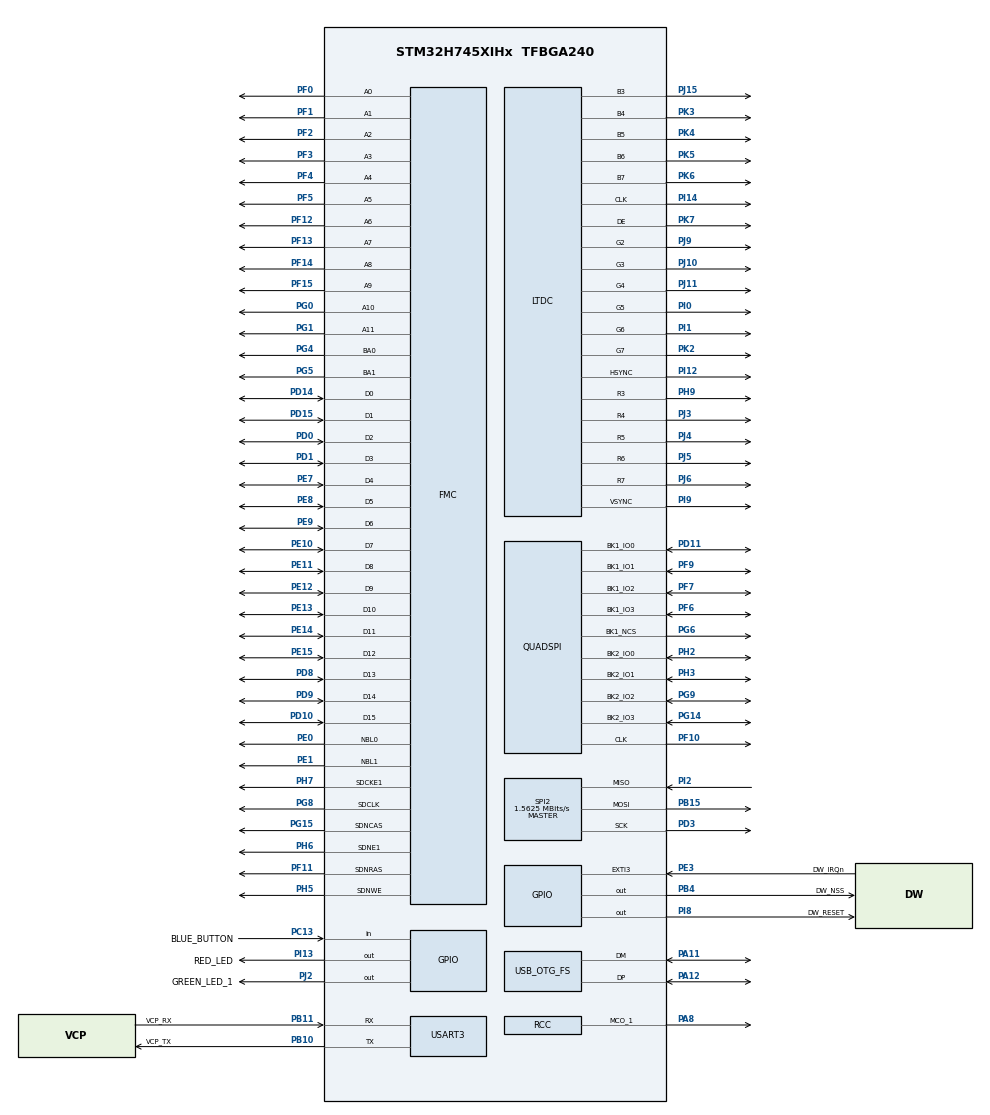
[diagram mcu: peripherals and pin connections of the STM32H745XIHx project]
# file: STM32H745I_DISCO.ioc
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CORTEX_M7.AccessPermission-Cortex_Memory_Protection_Unit_Region0_Settings=MPU_REGION_FULL_ACCESS
CORTEX_M7.AccessPermission-Cortex_Memory_Protection_Unit_Region1_Settings=MPU_REGION_FULL_ACCESS
CORTEX_M7.BaseAddress-Cortex_Memory_Protection_Unit_Region0_Settings=0xD0000000
CORTEX_M7.BaseAddress-Cortex_Memory_Protection_Unit_Region1_Settings=0x90000000
CORTEX_M7.CPU_DCache=Enabled
CORTEX_M7.CPU_ICache=Enabled
CORTEX_M7.DisableExec-Cortex_Memory_Protection_Unit_Region0_Settings=MPU_INSTRUCTION_ACCESS_DISABLE
CORTEX_M7.DisableExec-Cortex_Memory_Protection_Unit_Region1_Settings=MPU_INSTRUCTION_ACCESS_DISABLE
CORTEX_M7.Enable-Cortex_Memory_Protection_Unit_Region0_Settings=MPU_REGION_ENABLE
CORTEX_M7.Enable-Cortex_Memory_Protection_Unit_Region1_Settings=MPU_REGION_ENABLE
CORTEX_M7.Enable-Cortex_Memory_Protection_Unit_Region2_Settings=__NULL
CORTEX_M7.Enable-Cortex_Memory_Protection_Unit_Region3_Settings=__NULL
CORTEX_M7.Enable-Cortex_Memory_Protection_Unit_Region4_Settings=__NULL
CORTEX_M7.IsBufferable-Cortex_Memory_Protection_Unit_Region0_Settings=MPU_ACCESS_BUFFERABLE
CORTEX_M7.IsBufferable-Cortex_Memory_Protection_Unit_Region1_Settings=MPU_ACCESS_BUFFERABLE
CORTEX_M7.IsCacheable-Cortex_Memory_Protection_Unit_Region0_Settings=MPU_ACCESS_CACHEABLE
CORTEX_M7.IsCacheable-Cortex_Memory_Protection_Unit_Region1_Settings=MPU_ACCESS_CACHEABLE
CORTEX_M7.IsShareable-Cortex_Memory_Protection_Unit_Region1_Settings=MPU_ACCESS_NOT_SHAREABLE
CORTEX_M7.MPU_Control=MPU_PRIVILEGED_DEFAULT
CORTEX_M7.Size-Cortex_Memory_Protection_Unit_Region0_Settings=MPU_REGION_SIZE_1MB
CORTEX_M7.Size-Cortex_Memory_Protection_Unit_Region1_Settings=MPU_REGION_SIZE_128MB
CortexM4.IPs=CORTEX_M4\:I,DEBUG,FATFS_M4\:I,FREERTOS_M4\:I,IWDG2\:I,OPENAMP_M4\:I,PDM2PCM_M4\:I,PWR,RCC,RESMGR_UTILITY,SYS_M4\:I,USB_DEVICE_M4\:I,USB_HOST_M4\:I,VREFBUF,WWDG2\:I,DMA,BDMA,MDMA,NVIC2\:I
CortexM7.IPs=CORTEX_M7\:I,DEBUG\:I,FATFS_M7\:I,FREERTOS_M7\:I,IWDG1\:I,OPENAMP_M7\:I,PDM2PCM_M7\:I,PWR\:I,RCC\:I,RESMGR_UTILITY\:I,SYS\:I,USB_DEVICE_M7\:I,USB_HOST_M7\:I,VREFBUF\:I,WWDG1\:I,DMA\:I,BDMA\:I,MDMA\:I,NVIC1\:I,TIM6\:I,CRC\:I,LTDC\:I,DMA2D\:I,FMC\:I,QUADSPI\:I,STMicroelectronics.X-CUBE-TOUCHGFX.4.18.1_M7\:I,USART3\:I,SPI2\:I,USB_OTG_FS\:I
CortexM7.Pins=PB4 (NJTRST),PE3,PC13,PI8,PI13,PJ2
DMA2D.ColorMode=DMA2D_OUTPUT_RGB565
DMA2D.Mode=DMA2D_R2M
FMC.CASLatency2=FMC_SDRAM_CAS_LATENCY_2
FMC.ExitSelfRefreshDelay2=6
FMC.LoadToActiveDelay2=2
FMC.RCDDelay2=2
FMC.RPDelay1=2
FMC.RPDelay2=2
FMC.ReadBurst2=FMC_SDRAM_RBURST_ENABLE
FMC.RowCycleDelay1=6
FMC.RowCycleDelay2=6
FMC.SDClockPeriod2=FMC_SDRAM_CLOCK_PERIOD_2
FMC.SelfRefreshTime2=4
FMC.WriteRecoveryTime2=2
FREERTOS_M7.Tasks01=defaultTask,8,128,StartDefaultTask,Default,NULL,Dynamic,NULL,NULL;TouchGFXTask,24,3048,TouchGFX_Task,As weak,NULL,Dynamic,NULL,NULL
FREERTOS_M7.configTOTAL_HEAP_SIZE=32768
FREERTOS_M7.configUSE_NEWLIB_REENTRANT=0
LTDC.ActiveH=272
LTDC.ActiveW=480
LTDC.Alpha0_L0=0
LTDC.Alpha_L0=255
LTDC.BlendingFactor1_L0=LTDC_BLENDING_FACTOR1_CA
LTDC.BlendingFactor2_L0=LTDC_BLENDING_FACTOR2_CA
LTDC.FBStartAdress_L0=0xD0000000
LTDC.HBP=13
LTDC.HFP=32
LTDC.HSync=41
LTDC.ImageHeight_L0=272
LTDC.ImageWidth_L0=480
LTDC.Layers=0
LTDC.PixelFormat_L0=LTDC_PIXEL_FORMAT_RGB565
LTDC.VBP=2
LTDC.VSync=10
LTDC.WindowX1_L0=480
LTDC.WindowY1_L0=272
Mcu.Family=STM32H7
Mcu.Name=STM32H745XIHx
Mcu.Package=TFBGA240
NVIC1.DMA2D_IRQn=true\:5\:0\:false\:false\:true\:true\:true\:true
NVIC1.LTDC_IRQn=true\:5\:0\:false\:false\:true\:true\:true\:true
NVIC1.OTG_FS_IRQn=true\:5\:0\:false\:false\:true\:true\:false\:true
NVIC1.PriorityGroup=NVIC_PRIORITYGROUP_4
NVIC1.QUADSPI_IRQn=true\:5\:0\:false\:false\:true\:true\:true\:true
NVIC1.TIM6_DAC_IRQn=true\:15\:0\:false\:false\:true\:false\:false\:true
NVIC1.TimeBase=TIM6_DAC_IRQn
NVIC1.TimeBaseIP=TIM6
NVIC2.PriorityGroup=NVIC_PRIORITYGROUP_4
PA11.Mode=Device_Only
PA11.PinAttribute=CortexM7
PA11.Signal=USB_OTG_FS_DM
PA12.Mode=Device_Only
PA12.PinAttribute=CortexM7
PA12.Signal=USB_OTG_FS_DP
PA8.Mode=Clock-out-1
PA8.PinAttribute=CortexM7
PA8.Signal=RCC_MCO_1
PB10.GPIO_Label=VCP_TX
PB10.GPIO_Speed=GPIO_SPEED_FREQ_VERY_HIGH
PB10.Mode=Asynchronous
PB10.PinAttribute=CortexM7
PB10.Signal=USART3_TX
PB11.GPIO_Label=VCP_RX
PB11.GPIO_Speed=GPIO_SPEED_FREQ_VERY_HIGH
PB11.Mode=Asynchronous
PB11.PinAttribute=CortexM7
PB11.Signal=USART3_RX
PB15.GPIO_Speed=GPIO_SPEED_FREQ_VERY_HIGH
PB15.Mode=Full_Duplex_Master
PB15.PinAttribute=CortexM7
PB15.Signal=SPI2_MOSI
PB4\ (NJTRST).GPIO_Label=DW_NSS
PB4\ (NJTRST).GPIO_Speed=GPIO_SPEED_FREQ_VERY_HIGH
PB4\ (NJTRST).PinAttribute=CortexM7
PB4\ (NJTRST).PinState=GPIO_PIN_SET
PB4\ (NJTRST).Signal=GPIO_Output
PC13.GPIO_Label=BLUE_BUTTON
PC13.GPIO_PuPd=GPIO_PULLDOWN
PC13.PinAttribute=CortexM7
PC13.Signal=GPIO_Input
PD0.PinAttribute=CortexM7
PD0.Signal=FMC_D2_DA2
PD1.PinAttribute=CortexM7
PD1.Signal=FMC_D3_DA3
PD10.PinAttribute=CortexM7
PD10.Signal=FMC_D15_DA15
PD11.GPIO_Speed=GPIO_SPEED_FREQ_VERY_HIGH
PD11.Mode=Dual_Bank
PD11.PinAttribute=CortexM7
PD11.Signal=QUADSPI_BK1_IO0
PD14.PinAttribute=CortexM7
PD14.Signal=FMC_D0_DA0
PD15.PinAttribute=CortexM7
PD15.Signal=FMC_D1_DA1
PD3.GPIO_Speed=GPIO_SPEED_FREQ_VERY_HIGH
PD3.Mode=Full_Duplex_Master
PD3.PinAttribute=CortexM7
PD3.Signal=SPI2_SCK
PD8.PinAttribute=CortexM7
PD8.Signal=FMC_D13_DA13
PD9.PinAttribute=CortexM7
PD9.Signal=FMC_D14_DA14
PE0.PinAttribute=CortexM7
PE0.Signal=FMC_NBL0
PE1.PinAttribute=CortexM7
PE1.Signal=FMC_NBL1
PE10.PinAttribute=CortexM7
PE10.Signal=FMC_D7_DA7
PE11.PinAttribute=CortexM7
PE11.Signal=FMC_D8_DA8
PE12.PinAttribute=CortexM7
PE12.Signal=FMC_D9_DA9
PE13.PinAttribute=CortexM7
PE13.Signal=FMC_D10_DA10
PE14.PinAttribute=CortexM7
PE14.Signal=FMC_D11_DA11
PE15.PinAttribute=CortexM7
PE15.Signal=FMC_D12_DA12
PE3.GPIO_Label=DW_IRQn
PE3.GPIO_PuPd=GPIO_PULLDOWN
PE3.PinAttribute=CortexM7
PE3.Signal=GPXTI3
PE7.PinAttribute=CortexM7
PE7.Signal=FMC_D4_DA4
PE8.PinAttribute=CortexM7
PE8.Signal=FMC_D5_DA5
PE9.PinAttribute=CortexM7
PE9.Signal=FMC_D6_DA6
PF0.PinAttribute=CortexM7
PF0.Signal=FMC_A0
PF1.PinAttribute=CortexM7
PF1.Signal=FMC_A1
PF10.GPIO_Speed=GPIO_SPEED_FREQ_VERY_HIGH
PF10.Mode=Dual_Bank
PF10.PinAttribute=CortexM7
PF10.Signal=QUADSPI_CLK
PF11.PinAttribute=CortexM7
PF11.Signal=FMC_SDNRAS
PF12.PinAttribute=CortexM7
PF12.Signal=FMC_A6
PF13.PinAttribute=CortexM7
PF13.Signal=FMC_A7
PF14.PinAttribute=CortexM7
PF14.Signal=FMC_A8
PF15.PinAttribute=CortexM7
PF15.Signal=FMC_A9
PF2.PinAttribute=CortexM7
PF2.Signal=FMC_A2
PF3.PinAttribute=CortexM7
PF3.Signal=FMC_A3
PF4.PinAttribute=CortexM7
PF4.Signal=FMC_A4
PF5.PinAttribute=CortexM7
PF5.Signal=FMC_A5
PF6.GPIO_Speed=GPIO_SPEED_FREQ_VERY_HIGH
PF6.Mode=Dual_Bank
PF6.PinAttribute=CortexM7
PF6.Signal=QUADSPI_BK1_IO3
PF7.GPIO_Speed=GPIO_SPEED_FREQ_VERY_HIGH
PF7.Mode=Dual_Bank
PF7.PinAttribute=CortexM7
PF7.Signal=QUADSPI_BK1_IO2
PF9.GPIO_Speed=GPIO_SPEED_FREQ_VERY_HIGH
PF9.Mode=Dual_Bank
PF9.PinAttribute=CortexM7
PF9.Signal=QUADSPI_BK1_IO1
PG0.PinAttribute=CortexM7
PG0.Signal=FMC_A10
PG1.PinAttribute=CortexM7
PG1.Signal=FMC_A11
PG14.GPIO_Speed=GPIO_SPEED_FREQ_VERY_HIGH
PG14.Mode=Dual_Bank
PG14.PinAttribute=CortexM7
PG14.Signal=QUADSPI_BK2_IO3
PG15.PinAttribute=CortexM7
PG15.Signal=FMC_SDNCAS
PG4.PinAttribute=CortexM7
PG4.Signal=FMC_A14_BA0
PG5.PinAttribute=CortexM7
PG5.Signal=FMC_A15_BA1
PG6.GPIO_PuPd=GPIO_PULLUP
PG6.GPIO_Speed=GPIO_SPEED_FREQ_VERY_HIGH
PG6.Mode=Enable Chip Select 1 for both banks
PG6.PinAttribute=CortexM7
PG6.Signal=QUADSPI_BK1_NCS
PG8.PinAttribute=CortexM7
PG8.Signal=FMC_SDCLK
PG9.GPIO_Speed=GPIO_SPEED_FREQ_VERY_HIGH
PG9.Mode=Dual_Bank
PG9.PinAttribute=CortexM7
PG9.Signal=QUADSPI_BK2_IO2
PH0-OSC_IN\ (PH0).Mode=HSE-External-Oscillator
PH0-OSC_IN\ (PH0).PinAttribute=CortexM7
PH0-OSC_IN\ (PH0).Signal=RCC_OSC_IN
PH1-OSC_OUT\ (PH1).Mode=HSE-External-Oscillator
PH1-OSC_OUT\ (PH1).PinAttribute=CortexM7
PH1-OSC_OUT\ (PH1).Signal=RCC_OSC_OUT
PH2.GPIO_Speed=GPIO_SPEED_FREQ_VERY_HIGH
PH2.Mode=Dual_Bank
PH2.PinAttribute=CortexM7
PH2.Signal=QUADSPI_BK2_IO0
PH3.GPIO_Speed=GPIO_SPEED_FREQ_VERY_HIGH
PH3.Mode=Dual_Bank
PH3.PinAttribute=CortexM7
PH3.Signal=QUADSPI_BK2_IO1
PH5.PinAttribute=CortexM7
PH5.Signal=FMC_SDNWE
PH6.Mode=SdramChipSelect2_2
PH6.PinAttribute=CortexM7
PH6.Signal=FMC_SDNE1
PH7.Mode=SdramChipSelect2_2
PH7.PinAttribute=CortexM7
PH7.Signal=FMC_SDCKE1
PH9.GPIO_Speed=GPIO_SPEED_FREQ_HIGH
PH9.Mode=RGB565
PH9.PinAttribute=CortexM7
PH9.Signal=LTDC_R3
PI0.GPIO_Speed=GPIO_SPEED_FREQ_HIGH
PI0.Mode=RGB565
PI0.PinAttribute=CortexM7
PI0.Signal=LTDC_G5
PI1.GPIO_Speed=GPIO_SPEED_FREQ_HIGH
PI1.Mode=RGB565
PI1.PinAttribute=CortexM7
PI1.Signal=LTDC_G6
PI12.GPIO_Speed=GPIO_SPEED_FREQ_HIGH
PI12.Mode=RGB565
PI12.PinAttribute=CortexM7
PI12.Signal=LTDC_HSYNC
PI13.GPIO_Label=RED_LED
PI13.GPIO_Speed=GPIO_SPEED_FREQ_MEDIUM
PI13.PinAttribute=CortexM7
PI13.PinState=GPIO_PIN_SET
PI13.Signal=GPIO_Output
PI14.GPIO_Speed=GPIO_SPEED_FREQ_HIGH
PI14.Mode=RGB565
PI14.PinAttribute=CortexM7
PI14.Signal=LTDC_CLK
PI15.GPIO_Speed=GPIO_SPEED_FREQ_HIGH
PI15.PinAttribute=CortexM7
PI15.Signal=LTDC_R0
PI2.GPIO_Speed=GPIO_SPEED_FREQ_VERY_HIGH
PI2.Mode=Full_Duplex_Master
PI2.PinAttribute=CortexM7
PI2.Signal=SPI2_MISO
PI8.GPIO_Label=DW_RESET
PI8.PinAttribute=CortexM7
PI8.Signal=GPIO_Output
PI9.GPIO_Speed=GPIO_SPEED_FREQ_HIGH
PI9.Mode=RGB565
PI9.PinAttribute=CortexM7
PI9.Signal=LTDC_VSYNC
PJ0.GPIO_Speed=GPIO_SPEED_FREQ_HIGH
PJ0.PinAttribute=CortexM7
PJ0.Signal=LTDC_R1
PJ1.GPIO_Speed=GPIO_SPEED_FREQ_HIGH
PJ1.PinAttribute=CortexM7
PJ1.Signal=LTDC_R2
PJ10.GPIO_Speed=GPIO_SPEED_FREQ_HIGH
PJ10.Mode=RGB565
PJ10.PinAttribute=CortexM7
PJ10.Signal=LTDC_G3
PJ11.GPIO_Speed=GPIO_SPEED_FREQ_HIGH
PJ11.Mode=RGB565
PJ11.PinAttribute=CortexM7
PJ11.Signal=LTDC_G4
PJ12.GPIO_Speed=GPIO_SPEED_FREQ_HIGH
PJ12.PinAttribute=CortexM7
PJ12.Signal=LTDC_B0
PJ13.GPIO_Speed=GPIO_SPEED_FREQ_HIGH
PJ13.PinAttribute=CortexM7
PJ13.Signal=LTDC_B1
PJ14.GPIO_Speed=GPIO_SPEED_FREQ_HIGH
PJ14.PinAttribute=CortexM7
PJ14.Signal=LTDC_B2
PJ15.GPIO_Speed=GPIO_SPEED_FREQ_HIGH
PJ15.Mode=RGB565
PJ15.PinAttribute=CortexM7
PJ15.Signal=LTDC_B3
PJ2.GPIO_Label=GREEN_LED_1
PJ2.GPIO_Speed=GPIO_SPEED_FREQ_MEDIUM
PJ2.PinAttribute=CortexM7
PJ2.PinState=GPIO_PIN_SET
PJ2.Signal=GPIO_Output
PJ3.GPIO_Speed=GPIO_SPEED_FREQ_HIGH
PJ3.Mode=RGB565
PJ3.PinAttribute=CortexM7
PJ3.Signal=LTDC_R4
PJ4.GPIO_Speed=GPIO_SPEED_FREQ_HIGH
PJ4.Mode=RGB565
PJ4.PinAttribute=CortexM7
PJ4.Signal=LTDC_R5
PJ5.GPIO_Speed=GPIO_SPEED_FREQ_HIGH
PJ5.Mode=RGB565
PJ5.PinAttribute=CortexM7
PJ5.Signal=LTDC_R6
PJ6.GPIO_Speed=GPIO_SPEED_FREQ_HIGH
PJ6.Mode=RGB565
PJ6.PinAttribute=CortexM7
PJ6.Signal=LTDC_R7
PJ7.GPIO_Speed=GPIO_SPEED_FREQ_HIGH
PJ7.PinAttribute=CortexM7
PJ7.Signal=LTDC_G0
PJ8.GPIO_Speed=GPIO_SPEED_FREQ_HIGH
PJ8.PinAttribute=CortexM7
PJ8.Signal=LTDC_G1
PJ9.GPIO_Speed=GPIO_SPEED_FREQ_HIGH
PJ9.Mode=RGB565
PJ9.PinAttribute=CortexM7
PJ9.Signal=LTDC_G2
PK2.GPIO_Speed=GPIO_SPEED_FREQ_HIGH
PK2.Mode=RGB565
PK2.PinAttribute=CortexM7
PK2.Signal=LTDC_G7
PK3.GPIO_Speed=GPIO_SPEED_FREQ_HIGH
PK3.Mode=RGB565
PK3.PinAttribute=CortexM7
PK3.Signal=LTDC_B4
PK4.GPIO_Speed=GPIO_SPEED_FREQ_HIGH
PK4.Mode=RGB565
PK4.PinAttribute=CortexM7
PK4.Signal=LTDC_B5
PK5.GPIO_Speed=GPIO_SPEED_FREQ_HIGH
PK5.Mode=RGB565
PK5.PinAttribute=CortexM7
PK5.Signal=LTDC_B6
PK6.GPIO_Speed=GPIO_SPEED_FREQ_HIGH
PK6.Mode=RGB565
PK6.PinAttribute=CortexM7
PK6.Signal=LTDC_B7
PK7.GPIO_Speed=GPIO_SPEED_FREQ_HIGH
PK7.Mode=RGB565
PK7.PinAttribute=CortexM7
PK7.Signal=LTDC_DE
ProjectManager.HeapSize=M4-0x200,M7-0x1000
ProjectManager.StackSize=M4-0x400,M7-0x1000
ProjectManager.TargetToolchain=STM32CubeIDE
QUADSPI.ChipSelectHighTime=QSPI_CS_HIGH_TIME_3_CYCLE
QUADSPI.ClockPrescaler=1
QUADSPI.FlashSize=26
QUADSPI.SampleShifting=QSPI_SAMPLE_SHIFTING_HALFCYCLE
RCC.ADCFreq_Value=50390625
RCC.APB1Freq_Value=100000000
RCC.APB2Freq_Value=100000000
RCC.APB3Freq_Value=100000000
RCC.APB4Freq_Value=100000000
RCC.CortexFreq_Value=400000000
RCC.D1PPRE=RCC_APB3_DIV2
RCC.D2PPRE1=RCC_APB1_DIV2
RCC.D2PPRE2=RCC_APB2_DIV2
RCC.D3PPRE=RCC_APB4_DIV2
RCC.DIVM1=5
RCC.DIVM3=5
RCC.DIVN1=160
RCC.DIVN3=160
RCC.DIVQ1=4
RCC.DIVR3=83
RCC.HCLKFreq_Value=200000000
RCC.HPRE=RCC_HCLK_DIV2
RCC.PLLSourceVirtual=RCC_PLLSOURCE_HSE
RCC.PWR_Regulator_Voltage_Scale=PWR_REGULATOR_VOLTAGE_SCALE1
RCC.SYSCLKFreq_VALUE=400000000
RCC.SYSCLKSource=RCC_SYSCLKSOURCE_PLLCLK
RCC.USBCLockSelection=RCC_USBCLKSOURCE_HSI48
RCC.USBFreq_Value=48000000
SH.FMC_A0.0=FMC_A0,12b-sda2
SH.FMC_A1.0=FMC_A1,12b-sda2
SH.FMC_A10.0=FMC_A10,12b-sda2
SH.FMC_A11.0=FMC_A11,12b-sda2
SH.FMC_A14_BA0.0=FMC_BA0,FourSdramBanks2
SH.FMC_A15_BA1.0=FMC_BA1,FourSdramBanks2
SH.FMC_A2.0=FMC_A2,12b-sda2
SH.FMC_A3.0=FMC_A3,12b-sda2
SH.FMC_A4.0=FMC_A4,12b-sda2
SH.FMC_A5.0=FMC_A5,12b-sda2
SH.FMC_A6.0=FMC_A6,12b-sda2
SH.FMC_A7.0=FMC_A7,12b-sda2
SH.FMC_A8.0=FMC_A8,12b-sda2
SH.FMC_A9.0=FMC_A9,12b-sda2
SH.FMC_D0_DA0.0=FMC_D0,sd-16b-d2
SH.FMC_D10_DA10.0=FMC_D10,sd-16b-d2
SH.FMC_D11_DA11.0=FMC_D11,sd-16b-d2
SH.FMC_D12_DA12.0=FMC_D12,sd-16b-d2
SH.FMC_D13_DA13.0=FMC_D13,sd-16b-d2
SH.FMC_D14_DA14.0=FMC_D14,sd-16b-d2
SH.FMC_D15_DA15.0=FMC_D15,sd-16b-d2
SH.FMC_D1_DA1.0=FMC_D1,sd-16b-d2
SH.FMC_D2_DA2.0=FMC_D2,sd-16b-d2
SH.FMC_D3_DA3.0=FMC_D3,sd-16b-d2
SH.FMC_D4_DA4.0=FMC_D4,sd-16b-d2
SH.FMC_D5_DA5.0=FMC_D5,sd-16b-d2
SH.FMC_D6_DA6.0=FMC_D6,sd-16b-d2
SH.FMC_D7_DA7.0=FMC_D7,sd-16b-d2
SH.FMC_D8_DA8.0=FMC_D8,sd-16b-d2
SH.FMC_D9_DA9.0=FMC_D9,sd-16b-d2
SH.FMC_NBL0.0=FMC_NBL0,Sd2ByteEnable2
SH.FMC_NBL1.0=FMC_NBL1,Sd2ByteEnable2
SH.FMC_SDCLK.0=FMC_SDCLK,12b-sda2
SH.FMC_SDNCAS.0=FMC_SDNCAS,12b-sda2
SH.FMC_SDNRAS.0=FMC_SDNRAS,12b-sda2
SH.FMC_SDNWE.0=FMC_SDNWE,12b-sda2
SPI2.BaudRatePrescaler=SPI_BAUDRATEPRESCALER_128
SPI2.CalculateBaudRate=1.5625 MBits/s
SPI2.DataSize=SPI_DATASIZE_8BIT
SPI2.Direction=SPI_DIRECTION_2LINES
SPI2.Mode=SPI_MODE_MASTER
SPI2.VirtualType=VM_MASTER
STMicroelectronics.X-CUBE-TOUCHGFX.4.18.1_IsPackSelfContextualization=true
STMicroelectronics.X-CUBE-TOUCHGFX.4.18.1_M7.ApplicationCcGraphicsJjApplication=TouchGFXOoGenerator
STMicroelectronics.X-CUBE-TOUCHGFX.4.18.1_M7.tgfx_address1=0xD0000000
STMicroelectronics.X-CUBE-TOUCHGFX.4.18.1_M7.tgfx_address2=0xD0200000
STMicroelectronics.X-CUBE-TOUCHGFX.4.18.1_M7.tgfx_buffering_strategy=Double
STMicroelectronics.X-CUBE-TOUCHGFX.4.18.1_M7.tgfx_custom_height=272
STMicroelectronics.X-CUBE-TOUCHGFX.4.18.1_M7.tgfx_datareader=Disabled
STMicroelectronics.X-CUBE-TOUCHGFX.4.18.1_M7.tgfx_display_interface=disp_ltdc
STMicroelectronics.X-CUBE-TOUCHGFX.4.18.1_M7.tgfx_hardware_accelerator=dma_2d
STMicroelectronics.X-CUBE-TOUCHGFX.4.18.1_M7.tgfx_location=By Address
STMicroelectronics.X-CUBE-TOUCHGFX.4.18.1_M7.tgfx_vsync=vsync_ltdc
SYS.userName=SYS_M7
USART3.VirtualMode-Asynchronous=VM_ASYNC
USB_DEVICE_M7.CLASS_NAME_FS=MSC
USB_DEVICE_M7.CONFIGURATION_STRING_MSC_FS=UWBSurveying Config
USB_DEVICE_M7.INTERFACE_STRING_MSC_FS=UWBSurveying Interface
USB_DEVICE_M7.MANUFACTURER_STRING-MSC_FS=NC State
USB_DEVICE_M7.PRODUCT_STRING_MSC_FS=UWBSurveying
USB_DEVICE_M7.VirtualMode-MSC_FS=Msc
USB_DEVICE_M7.VirtualModeFS=Msc_FS
USB_OTG_FS.VirtualMode=Device_Only
VP_CRC_VS_CRC.Mode=CRC_Activate
VP_DMA2D_VS_DMA2D.Mode=DMA2D_Activate
VP_FREERTOS_M7_VS_CMSIS_V2.Mode=CMSIS_V2
VP_STMicroelectronics.X-CUBE-TOUCHGFX_M7_VS_GraphicsJjApplication_4.18.1.Mode=GraphicsJjApplication
VP_SYS_M4_VS_Systick.Mode=SysTick
VP_SYS_VS_tim6.Mode=TIM6
VP_USB_DEVICE_M7_VS_USB_DEVICE_MSC_FS.Mode=MSC_FS
board=custom

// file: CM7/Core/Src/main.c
/* USER CODE BEGIN Header */
/**
  ******************************************************************************
  * @file           : main.c
  * @brief          : Main program body
  ******************************************************************************
  * @attention
  *
  * <h2><center>&copy; Copyright (c) 2021 STMicroelectronics.
  * All rights reserved.</center></h2>
  *
  * This software component is licensed by ST under Ultimate Liberty license
  * SLA0044, the "License"; You may not use this file except in compliance with
  * the License. You may obtain a copy of the License at:
  *                             www.st.com/SLA0044
  *
  ******************************************************************************
  */
/* USER CODE END Header */
#include "main.h"
#include "cmsis_os.h"
#include "app_touchgfx.h"

/* USER CODE BEGIN Includes */
#include "main_user.h"
/* USER CODE END Includes */

/* USER CODE BEGIN PD */

#ifndef HSEM_ID_0
#define HSEM_ID_0 (0U) /* HW semaphore 0*/
#endif
/* USER CODE END PD */

CRC_HandleTypeDef hcrc;

DMA2D_HandleTypeDef hdma2d;

LTDC_HandleTypeDef hltdc;

QSPI_HandleTypeDef hqspi;

SPI_HandleTypeDef hspi2;

UART_HandleTypeDef huart3;

SDRAM_HandleTypeDef hsdram2;

/* Definitions for defaultTask */
osThreadId_t defaultTaskHandle;
const osThreadAttr_t defaultTask_attributes = {
  .name = "defaultTask",
  .stack_size = 128 * 4,
  .priority = (osPriority_t) osPriorityNormal,
};
/* Definitions for TouchGFXTask */
osThreadId_t TouchGFXTaskHandle;
const osThreadAttr_t TouchGFXTask_attributes = {
  .name = "TouchGFXTask",
  .stack_size = 3048 * 4,
  .priority = (osPriority_t) osPriorityNormal,
};
/* USER CODE BEGIN PV */
app_t app;
/* USER CODE END PV */

void SystemClock_Config(void);
static void MPU_Config(void);
static void MX_GPIO_Init(void);
static void MX_QUADSPI_Init(void);
static void MX_FMC_Init(void);
static void MX_LTDC_Init(void);
static void MX_CRC_Init(void);
static void MX_DMA2D_Init(void);
static void MX_USART3_UART_Init(void);
static void MX_SPI2_Init(void);
void StartDefaultTask(void *argument);
void TouchGFX_Task(void *argument);

/* USER CODE BEGIN PFP */
extern int dw_main(void);
/* USER CODE END PFP */

int main(void)
{
/* USER CODE BEGIN Boot_Mode_Sequence_0 */
  int32_t timeout;
/* USER CODE END Boot_Mode_Sequence_0 */

  /* MPU Configuration--------------------------------------------------------*/
  MPU_Config();

  /* Enable I-Cache---------------------------------------------------------*/
  SCB_EnableICache();

  /* Enable D-Cache---------------------------------------------------------*/
  SCB_EnableDCache();

/* USER CODE BEGIN Boot_Mode_Sequence_1 */
  /* Wait until CPU2 boots and enters in stop mode or timeout*/
  timeout = 0xFFFF;
  while((__HAL_RCC_GET_FLAG(RCC_FLAG_D2CKRDY) != RESET) && (timeout-- > 0));
  if ( timeout < 0 )
  {
  Error_Handler();
  }
/* USER CODE END Boot_Mode_Sequence_1 */
  /* MCU Configuration--------------------------------------------------------*/

  /* Reset of all peripherals, Initializes the Flash interface and the Systick. */
  HAL_Init();

  /* Configure the system clock */
  SystemClock_Config();
/* USER CODE BEGIN Boot_Mode_Sequence_2 */
/* When system initialization is finished, Cortex-M7 will release Cortex-M4 by means of
HSEM notification */
/*HW semaphore Clock enable*/
__HAL_RCC_HSEM_CLK_ENABLE();
/*Take HSEM */
HAL_HSEM_FastTake(HSEM_ID_0);
/*Release HSEM in order to notify the CPU2(CM4)*/
HAL_HSEM_Release(HSEM_ID_0,0);
/* wait until CPU2 wakes up from stop mode */
timeout = 0xFFFF;
while((__HAL_RCC_GET_FLAG(RCC_FLAG_D2CKRDY) == RESET) && (timeout-- > 0));
if ( timeout < 0 )
{
Error_Handler();
}
/* USER CODE END Boot_Mode_Sequence_2 */

  /* Initialize all configured peripherals */
  MX_GPIO_Init();
  MX_QUADSPI_Init();
  MX_FMC_Init();
  MX_LTDC_Init();
  MX_CRC_Init();
  MX_DMA2D_Init();
  MX_USART3_UART_Init();
  MX_SPI2_Init();
  MX_TouchGFX_Init();
  /* USER CODE BEGIN 2 */

  setup_DW1000RSTnIRQ(0);

  stdio_init(&huart3);
  /* USER CODE END 2 */

  /* Init scheduler */
  osKernelInitialize();

  /* Create the thread(s) */
  /* creation of defaultTask */
  defaultTaskHandle = osThreadNew(StartDefaultTask, NULL, &defaultTask_attributes);

  /* creation of TouchGFXTask */
  TouchGFXTaskHandle = osThreadNew(TouchGFX_Task, NULL, &TouchGFXTask_attributes);

  /* Start scheduler */
  osKernelStart();

  /* We should never get here as control is now taken by the scheduler */
  /* Infinite loop */
  while (1)
  {

  }
}

void SystemClock_Config(void)
{
  RCC_OscInitTypeDef RCC_OscInitStruct = {0};
  RCC_ClkInitTypeDef RCC_ClkInitStruct = {0};

  /** Supply configuration update enable
  */
  HAL_PWREx_ConfigSupply(PWR_DIRECT_SMPS_SUPPLY);
  /** Configure the main internal regulator output voltage
  */
  __HAL_PWR_VOLTAGESCALING_CONFIG(PWR_REGULATOR_VOLTAGE_SCALE1);

  while(!__HAL_PWR_GET_FLAG(PWR_FLAG_VOSRDY)) {}
  /** Macro to configure the PLL clock source
  */
  __HAL_RCC_PLL_PLLSOURCE_CONFIG(RCC_PLLSOURCE_HSE);
  /** Initializes the RCC Oscillators according to the specified parameters
  * in the RCC_OscInitTypeDef structure.
  */
  RCC_OscInitStruct.OscillatorType = RCC_OSCILLATORTYPE_HSI|RCC_OSCILLATORTYPE_HSE;
  RCC_OscInitStruct.HSEState = RCC_HSE_ON;
  RCC_OscInitStruct.HSIState = RCC_HSI_DIV1;
  RCC_OscInitStruct.HSICalibrationValue = RCC_HSICALIBRATION_DEFAULT;
  RCC_OscInitStruct.PLL.PLLState = RCC_PLL_ON;
  RCC_OscInitStruct.PLL.PLLSource = RCC_PLLSOURCE_HSE;
  RCC_OscInitStruct.PLL.PLLM = 5;
  RCC_OscInitStruct.PLL.PLLN = 160;
  RCC_OscInitStruct.PLL.PLLP = 2;
  RCC_OscInitStruct.PLL.PLLQ = 4;
  RCC_OscInitStruct.PLL.PLLR = 2;
  RCC_OscInitStruct.PLL.PLLRGE = RCC_PLL1VCIRANGE_2;
  RCC_OscInitStruct.PLL.PLLVCOSEL = RCC_PLL1VCOWIDE;
  RCC_OscInitStruct.PLL.PLLFRACN = 0;
  if (HAL_RCC_OscConfig(&RCC_OscInitStruct) != HAL_OK)
  {
    Error_Handler();
  }
  /** Initializes the CPU, AHB and APB buses clocks
  */
  RCC_ClkInitStruct.ClockType = RCC_CLOCKTYPE_HCLK|RCC_CLOCKTYPE_SYSCLK
                              |RCC_CLOCKTYPE_PCLK1|RCC_CLOCKTYPE_PCLK2
                              |RCC_CLOCKTYPE_D3PCLK1|RCC_CLOCKTYPE_D1PCLK1;
  RCC_ClkInitStruct.SYSCLKSource = RCC_SYSCLKSOURCE_PLLCLK;
  RCC_ClkInitStruct.SYSCLKDivider = RCC_SYSCLK_DIV1;
  RCC_ClkInitStruct.AHBCLKDivider = RCC_HCLK_DIV2;
  RCC_ClkInitStruct.APB3CLKDivider = RCC_APB3_DIV2;
  RCC_ClkInitStruct.APB1CLKDivider = RCC_APB1_DIV2;
  RCC_ClkInitStruct.APB2CLKDivider = RCC_APB2_DIV2;
  RCC_ClkInitStruct.APB4CLKDivider = RCC_APB4_DIV2;

  if (HAL_RCC_ClockConfig(&RCC_ClkInitStruct, FLASH_LATENCY_2) != HAL_OK)
  {
    Error_Handler();
  }
  HAL_RCC_MCOConfig(RCC_MCO1, RCC_MCO1SOURCE_HSI, RCC_MCODIV_1);
}

static void MX_CRC_Init(void)
{

  hcrc.Instance = CRC;
  hcrc.Init.DefaultPolynomialUse = DEFAULT_POLYNOMIAL_ENABLE;
  hcrc.Init.DefaultInitValueUse = DEFAULT_INIT_VALUE_ENABLE;
  hcrc.Init.InputDataInversionMode = CRC_INPUTDATA_INVERSION_NONE;
  hcrc.Init.OutputDataInversionMode = CRC_OUTPUTDATA_INVERSION_DISABLE;
  hcrc.InputDataFormat = CRC_INPUTDATA_FORMAT_BYTES;
  if (HAL_CRC_Init(&hcrc) != HAL_OK)
  {
    Error_Handler();
  }

}

static void MX_DMA2D_Init(void)
{

  hdma2d.Instance = DMA2D;
  hdma2d.Init.Mode = DMA2D_R2M;
  hdma2d.Init.ColorMode = DMA2D_OUTPUT_RGB565;
  hdma2d.Init.OutputOffset = 0;
  if (HAL_DMA2D_Init(&hdma2d) != HAL_OK)
  {
    Error_Handler();
  }

}

static void MX_LTDC_Init(void)
{

  /* USER CODE BEGIN LTDC_Init 0 */
  initLtdcClocks();
  /* USER CODE END LTDC_Init 0 */

  LTDC_LayerCfgTypeDef pLayerCfg = {0};

  hltdc.Instance = LTDC;
  hltdc.Init.HSPolarity = LTDC_HSPOLARITY_AL;
  hltdc.Init.VSPolarity = LTDC_VSPOLARITY_AL;
  hltdc.Init.DEPolarity = LTDC_DEPOLARITY_AL;
  hltdc.Init.PCPolarity = LTDC_PCPOLARITY_IPC;
  hltdc.Init.HorizontalSync = 40;
  hltdc.Init.VerticalSync = 9;
  hltdc.Init.AccumulatedHBP = 53;
  hltdc.Init.AccumulatedVBP = 11;
  hltdc.Init.AccumulatedActiveW = 533;
  hltdc.Init.AccumulatedActiveH = 283;
  hltdc.Init.TotalWidth = 565;
  hltdc.Init.TotalHeigh = 285;
  hltdc.Init.Backcolor.Blue = 0;
  hltdc.Init.Backcolor.Green = 0;
  hltdc.Init.Backcolor.Red = 0;
  if (HAL_LTDC_Init(&hltdc) != HAL_OK)
  {
    Error_Handler();
  }
  pLayerCfg.WindowX0 = 0;
  pLayerCfg.WindowX1 = 480;
  pLayerCfg.WindowY0 = 0;
  pLayerCfg.WindowY1 = 272;
  pLayerCfg.PixelFormat = LTDC_PIXEL_FORMAT_RGB565;
  pLayerCfg.Alpha = 255;
  pLayerCfg.Alpha0 = 0;
  pLayerCfg.BlendingFactor1 = LTDC_BLENDING_FACTOR1_CA;
  pLayerCfg.BlendingFactor2 = LTDC_BLENDING_FACTOR2_CA;
  pLayerCfg.FBStartAdress = 0xD0000000;
  pLayerCfg.ImageWidth = 480;
  pLayerCfg.ImageHeight = 272;
  pLayerCfg.Backcolor.Blue = 0;
  pLayerCfg.Backcolor.Green = 0;
  pLayerCfg.Backcolor.Red = 0;
  if (HAL_LTDC_ConfigLayer(&hltdc, &pLayerCfg, 0) != HAL_OK)
  {
    Error_Handler();
  }

}

static void MX_QUADSPI_Init(void)
{

  /* QUADSPI parameter configuration*/
  hqspi.Instance = QUADSPI;
  hqspi.Init.ClockPrescaler = 1;
  hqspi.Init.FifoThreshold = 1;
  hqspi.Init.SampleShifting = QSPI_SAMPLE_SHIFTING_HALFCYCLE;
  hqspi.Init.FlashSize = 26;
  hqspi.Init.ChipSelectHighTime = QSPI_CS_HIGH_TIME_3_CYCLE;
  hqspi.Init.ClockMode = QSPI_CLOCK_MODE_0;
  hqspi.Init.DualFlash = QSPI_DUALFLASH_ENABLE;
  if (HAL_QSPI_Init(&hqspi) != HAL_OK)
  {
    Error_Handler();
  }
  /* USER CODE BEGIN QUADSPI_Init 2 */
  initBspQuadSpi(&Error_Handler);
  /* USER CODE END QUADSPI_Init 2 */

}

static void MX_SPI2_Init(void)
{

  /* SPI2 parameter configuration*/
  hspi2.Instance = SPI2;
  hspi2.Init.Mode = SPI_MODE_MASTER;
  hspi2.Init.Direction = SPI_DIRECTION_2LINES;
  hspi2.Init.DataSize = SPI_DATASIZE_8BIT;
  hspi2.Init.CLKPolarity = SPI_POLARITY_LOW;
  hspi2.Init.CLKPhase = SPI_PHASE_1EDGE;
  hspi2.Init.NSS = SPI_NSS_SOFT;
  hspi2.Init.BaudRatePrescaler = SPI_BAUDRATEPRESCALER_128;
  hspi2.Init.FirstBit = SPI_FIRSTBIT_MSB;
  hspi2.Init.TIMode = SPI_TIMODE_DISABLE;
  hspi2.Init.CRCCalculation = SPI_CRCCALCULATION_DISABLE;
  hspi2.Init.CRCPolynomial = 0x0;
  hspi2.Init.NSSPMode = SPI_NSS_PULSE_ENABLE;
  hspi2.Init.NSSPolarity = SPI_NSS_POLARITY_LOW;
  hspi2.Init.FifoThreshold = SPI_FIFO_THRESHOLD_01DATA;
  hspi2.Init.TxCRCInitializationPattern = SPI_CRC_INITIALIZATION_ALL_ZERO_PATTERN;
  hspi2.Init.RxCRCInitializationPattern = SPI_CRC_INITIALIZATION_ALL_ZERO_PATTERN;
  hspi2.Init.MasterSSIdleness = SPI_MASTER_SS_IDLENESS_00CYCLE;
  hspi2.Init.MasterInterDataIdleness = SPI_MASTER_INTERDATA_IDLENESS_00CYCLE;
  hspi2.Init.MasterReceiverAutoSusp = SPI_MASTER_RX_AUTOSUSP_DISABLE;
  hspi2.Init.MasterKeepIOState = SPI_MASTER_KEEP_IO_STATE_DISABLE;
  hspi2.Init.IOSwap = SPI_IO_SWAP_DISABLE;
  if (HAL_SPI_Init(&hspi2) != HAL_OK)
  {
    Error_Handler();
  }

}

static void MX_USART3_UART_Init(void)
{

  huart3.Instance = USART3;
  huart3.Init.BaudRate = 115200;
  huart3.Init.WordLength = UART_WORDLENGTH_8B;
  huart3.Init.StopBits = UART_STOPBITS_1;
  huart3.Init.Parity = UART_PARITY_NONE;
  huart3.Init.Mode = UART_MODE_TX_RX;
  huart3.Init.HwFlowCtl = UART_HWCONTROL_NONE;
  huart3.Init.OverSampling = UART_OVERSAMPLING_16;
  huart3.Init.OneBitSampling = UART_ONE_BIT_SAMPLE_DISABLE;
  huart3.Init.ClockPrescaler = UART_PRESCALER_DIV1;
  huart3.AdvancedInit.AdvFeatureInit = UART_ADVFEATURE_NO_INIT;
  if (HAL_UART_Init(&huart3) != HAL_OK)
  {
    Error_Handler();
  }
  if (HAL_UARTEx_SetTxFifoThreshold(&huart3, UART_TXFIFO_THRESHOLD_1_8) != HAL_OK)
  {
    Error_Handler();
  }
  if (HAL_UARTEx_SetRxFifoThreshold(&huart3, UART_RXFIFO_THRESHOLD_1_8) != HAL_OK)
  {
    Error_Handler();
  }
  if (HAL_UARTEx_DisableFifoMode(&huart3) != HAL_OK)
  {
    Error_Handler();
  }

}

/* FMC initialization function */
void MX_FMC_Init(void)
{

  FMC_SDRAM_TimingTypeDef SdramTiming = {0};

  /** Perform the SDRAM2 memory initialization sequence
  */
  hsdram2.Instance = FMC_SDRAM_DEVICE;
  /* hsdram2.Init */
  hsdram2.Init.SDBank = FMC_SDRAM_BANK2;
  hsdram2.Init.ColumnBitsNumber = FMC_SDRAM_COLUMN_BITS_NUM_8;
  hsdram2.Init.RowBitsNumber = FMC_SDRAM_ROW_BITS_NUM_12;
  hsdram2.Init.MemoryDataWidth = FMC_SDRAM_MEM_BUS_WIDTH_16;
  hsdram2.Init.InternalBankNumber = FMC_SDRAM_INTERN_BANKS_NUM_4;
  hsdram2.Init.CASLatency = FMC_SDRAM_CAS_LATENCY_2;
  hsdram2.Init.WriteProtection = FMC_SDRAM_WRITE_PROTECTION_DISABLE;
  hsdram2.Init.SDClockPeriod = FMC_SDRAM_CLOCK_PERIOD_2;
  hsdram2.Init.ReadBurst = FMC_SDRAM_RBURST_ENABLE;
  hsdram2.Init.ReadPipeDelay = FMC_SDRAM_RPIPE_DELAY_0;
  /* SdramTiming */
  SdramTiming.LoadToActiveDelay = 2;
  SdramTiming.ExitSelfRefreshDelay = 6;
  SdramTiming.SelfRefreshTime = 4;
  SdramTiming.RowCycleDelay = 6;
  SdramTiming.WriteRecoveryTime = 2;
  SdramTiming.RPDelay = 2;
  SdramTiming.RCDDelay = 2;

  if (HAL_SDRAM_Init(&hsdram2, &SdramTiming) != HAL_OK)
  {
    Error_Handler( );
  }

  /* USER CODE BEGIN FMC_Init 2 */
  initBspSdRam(&Error_Handler);
  /* USER CODE END FMC_Init 2 */
}

static void MX_GPIO_Init(void)
{
  GPIO_InitTypeDef GPIO_InitStruct = {0};

  /* GPIO Ports Clock Enable */
  __HAL_RCC_GPIOK_CLK_ENABLE();
  __HAL_RCC_GPIOG_CLK_ENABLE();
  __HAL_RCC_GPIOI_CLK_ENABLE();
  __HAL_RCC_GPIOE_CLK_ENABLE();
  __HAL_RCC_GPIOB_CLK_ENABLE();
  __HAL_RCC_GPIOJ_CLK_ENABLE();
  __HAL_RCC_GPIOD_CLK_ENABLE();
  __HAL_RCC_GPIOC_CLK_ENABLE();
  __HAL_RCC_GPIOA_CLK_ENABLE();
  __HAL_RCC_GPIOF_CLK_ENABLE();
  __HAL_RCC_GPIOH_CLK_ENABLE();

  /*Configure GPIO pin Output Level */
  HAL_GPIO_WritePin(DW_NSS_GPIO_Port, DW_NSS_Pin, GPIO_PIN_SET);

  /*Configure GPIO pin Output Level */
  HAL_GPIO_WritePin(DW_RESET_GPIO_Port, DW_RESET_Pin, GPIO_PIN_RESET);

  /*Configure GPIO pin Output Level */
  HAL_GPIO_WritePin(RED_LED_GPIO_Port, RED_LED_Pin, GPIO_PIN_SET);

  /*Configure GPIO pin Output Level */
  HAL_GPIO_WritePin(GREEN_LED_1_GPIO_Port, GREEN_LED_1_Pin, GPIO_PIN_SET);

  /*Configure GPIO pin : DW_NSS_Pin */
  GPIO_InitStruct.Pin = DW_NSS_Pin;
  GPIO_InitStruct.Mode = GPIO_MODE_OUTPUT_PP;
  GPIO_InitStruct.Pull = GPIO_NOPULL;
  GPIO_InitStruct.Speed = GPIO_SPEED_FREQ_VERY_HIGH;
  HAL_GPIO_Init(DW_NSS_GPIO_Port, &GPIO_InitStruct);

  /*Configure GPIO pin : DW_IRQn_Pin */
  GPIO_InitStruct.Pin = DW_IRQn_Pin;
  GPIO_InitStruct.Mode = GPIO_MODE_IT_RISING;
  GPIO_InitStruct.Pull = GPIO_PULLDOWN;
  HAL_GPIO_Init(DW_IRQn_GPIO_Port, &GPIO_InitStruct);

  /*Configure GPIO pin : BLUE_BUTTON_Pin */
  GPIO_InitStruct.Pin = BLUE_BUTTON_Pin;
  GPIO_InitStruct.Mode = GPIO_MODE_INPUT;
  GPIO_InitStruct.Pull = GPIO_PULLDOWN;
  HAL_GPIO_Init(BLUE_BUTTON_GPIO_Port, &GPIO_InitStruct);

  /*Configure GPIO pin : DW_RESET_Pin */
  GPIO_InitStruct.Pin = DW_RESET_Pin;
  GPIO_InitStruct.Mode = GPIO_MODE_OUTPUT_PP;
  GPIO_InitStruct.Pull = GPIO_NOPULL;
  GPIO_InitStruct.Speed = GPIO_SPEED_FREQ_LOW;
  HAL_GPIO_Init(DW_RESET_GPIO_Port, &GPIO_InitStruct);

  /*Configure GPIO pin : PA8 */
  GPIO_InitStruct.Pin = GPIO_PIN_8;
  GPIO_InitStruct.Mode = GPIO_MODE_AF_PP;
  GPIO_InitStruct.Pull = GPIO_NOPULL;
  GPIO_InitStruct.Speed = GPIO_SPEED_FREQ_LOW;
  GPIO_InitStruct.Alternate = GPIO_AF0_MCO;
  HAL_GPIO_Init(GPIOA, &GPIO_InitStruct);

  /*Configure GPIO pin : RED_LED_Pin */
  GPIO_InitStruct.Pin = RED_LED_Pin;
  GPIO_InitStruct.Mode = GPIO_MODE_OUTPUT_PP;
  GPIO_InitStruct.Pull = GPIO_NOPULL;
  GPIO_InitStruct.Speed = GPIO_SPEED_FREQ_MEDIUM;
  HAL_GPIO_Init(RED_LED_GPIO_Port, &GPIO_InitStruct);

  /*Configure GPIO pin : GREEN_LED_1_Pin */
  GPIO_InitStruct.Pin = GREEN_LED_1_Pin;
  GPIO_InitStruct.Mode = GPIO_MODE_OUTPUT_PP;
  GPIO_InitStruct.Pull = GPIO_NOPULL;
  GPIO_InitStruct.Speed = GPIO_SPEED_FREQ_MEDIUM;
  HAL_GPIO_Init(GREEN_LED_1_GPIO_Port, &GPIO_InitStruct);

}

void StartDefaultTask(void *argument)
{
  /* USER CODE BEGIN 5 */
  dw_main();
  /* Infinite loop */
  for(;;)
  {
	  osDelay(1);
  }
  /* USER CODE END 5 */
}

__weak void TouchGFX_Task(void *argument)
{
  for(;;)
  {
    osDelay(1);
  }
}

/* MPU Configuration */

void MPU_Config(void)
{
  MPU_Region_InitTypeDef MPU_InitStruct = {0};

  /* Disables the MPU */
  HAL_MPU_Disable();
  /** Initializes and configures the Region and the memory to be protected
  */
  MPU_InitStruct.Enable = MPU_REGION_ENABLE;
  MPU_InitStruct.Number = MPU_REGION_NUMBER0;
  MPU_InitStruct.BaseAddress = 0xD0000000;
  MPU_InitStruct.Size = MPU_REGION_SIZE_1MB;
  MPU_InitStruct.SubRegionDisable = 0x0;
  MPU_InitStruct.TypeExtField = MPU_TEX_LEVEL0;
  MPU_InitStruct.AccessPermission = MPU_REGION_FULL_ACCESS;
  MPU_InitStruct.DisableExec = MPU_INSTRUCTION_ACCESS_DISABLE;
  MPU_InitStruct.IsShareable = MPU_ACCESS_NOT_SHAREABLE;
  MPU_InitStruct.IsCacheable = MPU_ACCESS_CACHEABLE;
  MPU_InitStruct.IsBufferable = MPU_ACCESS_BUFFERABLE;

  HAL_MPU_ConfigRegion(&MPU_InitStruct);
  /** Initializes and configures the Region and the memory to be protected
  */
  MPU_InitStruct.Number = MPU_REGION_NUMBER1;
  MPU_InitStruct.BaseAddress = 0x90000000;
  MPU_InitStruct.Size = MPU_REGION_SIZE_128MB;

  HAL_MPU_ConfigRegion(&MPU_InitStruct);
  /* Enables the MPU */
  HAL_MPU_Enable(MPU_PRIVILEGED_DEFAULT);

}

void HAL_TIM_PeriodElapsedCallback(TIM_HandleTypeDef *htim)
{
  if (htim->Instance == TIM6) {
    HAL_IncTick();
  }
}

void Error_Handler(void)
{
  __disable_irq();
  while (1)
  {
  }
}
